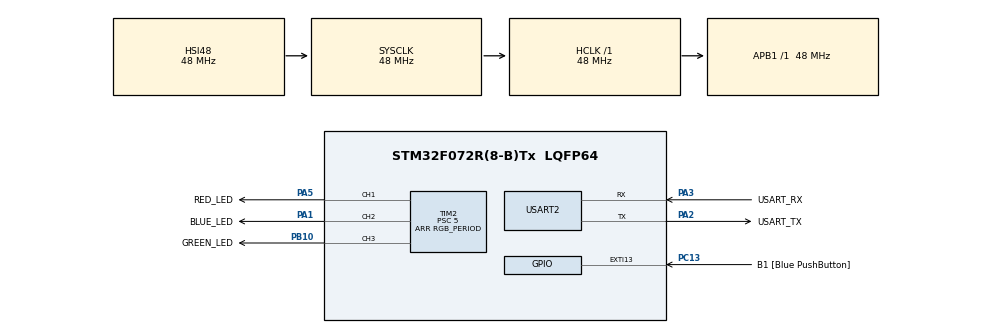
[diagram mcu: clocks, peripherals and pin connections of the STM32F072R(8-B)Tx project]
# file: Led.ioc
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Mcu.Family=STM32F0
Mcu.Name=STM32F072R(8-B)Tx
Mcu.Package=LQFP64
Mcu.UserConstants=RGB_PERIOD,7999;INITIAL_MAX_DUTY,RGB_PERIOD
NVIC.TIM2_IRQn=true\:0\:0\:false\:false\:true\:true\:true\:true
PA1.GPIO_Label=BLUE_LED
PA1.Signal=S_TIM2_CH2
PA13.GPIO_Label=TMS
PA13.Mode=Serial_Wire
PA13.Signal=SYS_SWDIO
PA14.GPIO_Label=TCK
PA14.Mode=Serial_Wire
PA14.Signal=SYS_SWCLK
PA2.GPIO_Label=USART_TX
PA2.GPIO_Mode=GPIO_MODE_AF_PP
PA2.GPIO_PuPd=GPIO_NOPULL
PA2.GPIO_Speed=GPIO_SPEED_FREQ_LOW
PA2.Mode=Asynchronous
PA2.Signal=USART2_TX
PA3.GPIO_Label=USART_RX
PA3.GPIO_Mode=GPIO_MODE_AF_PP
PA3.GPIO_PuPd=GPIO_NOPULL
PA3.GPIO_Speed=GPIO_SPEED_FREQ_LOW
PA3.Mode=Asynchronous
PA3.Signal=USART2_RX
PA5.GPIO_Label=RED_LED
PA5.Signal=S_TIM2_CH1_ETR
PB10.GPIO_Label=GREEN_LED
PB10.Signal=S_TIM2_CH3
PC13.GPIO_Label=B1 [Blue PushButton]
PC13.GPIO_ModeDefaultEXTI=GPIO_MODE_IT_FALLING
PC13.Signal=GPXTI13
PC14-OSC32_IN.Mode=LSE-External-Oscillator
PC14-OSC32_IN.Signal=RCC_OSC32_IN
PC15-OSC32_OUT.Mode=LSE-External-Oscillator
PC15-OSC32_OUT.Signal=RCC_OSC32_OUT
PF0-OSC_IN.Mode=HSE-External-Clock-Source
PF0-OSC_IN.Signal=RCC_OSC_IN
PF1-OSC_OUT.Signal=RCC_OSC_OUT
ProjectManager.HeapSize=0x200
ProjectManager.StackSize=0x400
ProjectManager.TargetToolchain=STM32CubeIDE
RCC.AHBFreq_Value=48000000
RCC.APB1Freq_Value=48000000
RCC.APB1TimFreq_Value=48000000
RCC.FLatency-AdvancedSettings=FLASH_LATENCY_1
RCC.HCLKFreq_Value=48000000
RCC.PLLDivider=RCC_PREDIV_DIV2
RCC.PLLMUL=RCC_PLL_MUL12
RCC.PREFETCH_ENABLE-AdvancedSettings=1
RCC.SYSCLKFreq_VALUE=48000000
RCC.SYSCLKSource=RCC_SYSCLKSOURCE_HSI48
SH.S_TIM2_CH1_ETR.0=TIM2_CH1,PWM Generation1 CH1
SH.S_TIM2_CH2.0=TIM2_CH2,PWM Generation2 CH2
SH.S_TIM2_CH3.0=TIM2_CH3,PWM Generation3 CH3
TIM2.Channel-PWM\ Generation1\ CH1=TIM_CHANNEL_1
TIM2.Channel-PWM\ Generation2\ CH2=TIM_CHANNEL_2
TIM2.Channel-PWM\ Generation3\ CH3=TIM_CHANNEL_3
TIM2.Period=RGB_PERIOD
TIM2.Prescaler=5
TIM2.Pulse-PWM\ Generation1\ CH1=INITIAL_MAX_DUTY
TIM2.Pulse-PWM\ Generation2\ CH2=INITIAL_MAX_DUTY
TIM2.Pulse-PWM\ Generation3\ CH3=INITIAL_MAX_DUTY
USART2.VirtualMode=VM_ASYNC
USART2.VirtualMode-Asynchronous=VM_ASYNC
board=NUCLEO-F072RB

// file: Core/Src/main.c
/* USER CODE BEGIN Header */
/**
  ******************************************************************************
  * @file           : main.c
  * @brief          : Main program body
  ******************************************************************************
  * @attention
  *
  * Copyright (c) 2022 STMicroelectronics.
  * All rights reserved.
  *
  * This software is licensed under terms that can be found in the LICENSE file
  * in the root directory of this software component.
  * If no LICENSE file comes with this software, it is provided AS-IS.
  *
  ******************************************************************************
  */
/* USER CODE END Header */
#include "main.h"
#include "tim.h"
#include "usart.h"
#include "gpio.h"

/* USER CODE BEGIN Includes */
#include "rgb_sample_routine.h"
/* USER CODE END Includes */

void SystemClock_Config(void);

int main(void)
{

  /* MCU Configuration--------------------------------------------------------*/

  /* Reset of all peripherals, Initializes the Flash interface and the Systick. */
  HAL_Init();

  /* Configure the system clock */
  SystemClock_Config();

  /* Initialize all configured peripherals */
  MX_GPIO_Init();
  MX_USART2_UART_Init();
  MX_TIM2_Init();
  /* USER CODE BEGIN 2 */
//  rgbLedStateInit();
  ledRoutine_Init();
  /* USER CODE END 2 */

  /* Infinite loop */
  while (1)
  {

    /* USER CODE BEGIN 3 */
  ledRoutine_Update();

  }
  /* USER CODE END 3 */
}

void SystemClock_Config(void)
{
  RCC_OscInitTypeDef RCC_OscInitStruct = {0};
  RCC_ClkInitTypeDef RCC_ClkInitStruct = {0};
  RCC_PeriphCLKInitTypeDef PeriphClkInit = {0};

  /** Initializes the RCC Oscillators according to the specified parameters
  * in the RCC_OscInitTypeDef structure.
  */
  RCC_OscInitStruct.OscillatorType = RCC_OSCILLATORTYPE_HSI48;
  RCC_OscInitStruct.HSI48State = RCC_HSI48_ON;
  RCC_OscInitStruct.PLL.PLLState = RCC_PLL_NONE;
  if (HAL_RCC_OscConfig(&RCC_OscInitStruct) != HAL_OK)
  {
    Error_Handler();
  }

  /** Initializes the CPU, AHB and APB buses clocks
  */
  RCC_ClkInitStruct.ClockType = RCC_CLOCKTYPE_HCLK|RCC_CLOCKTYPE_SYSCLK
                              |RCC_CLOCKTYPE_PCLK1;
  RCC_ClkInitStruct.SYSCLKSource = RCC_SYSCLKSOURCE_HSI48;
  RCC_ClkInitStruct.AHBCLKDivider = RCC_SYSCLK_DIV1;
  RCC_ClkInitStruct.APB1CLKDivider = RCC_HCLK_DIV1;

  if (HAL_RCC_ClockConfig(&RCC_ClkInitStruct, FLASH_LATENCY_1) != HAL_OK)
  {
    Error_Handler();
  }
  PeriphClkInit.PeriphClockSelection = RCC_PERIPHCLK_USART2;
  PeriphClkInit.Usart2ClockSelection = RCC_USART2CLKSOURCE_PCLK1;
  if (HAL_RCCEx_PeriphCLKConfig(&PeriphClkInit) != HAL_OK)
  {
    Error_Handler();
  }
}

void Error_Handler(void)
{
  __disable_irq();
  while (1)
  {
  }
}
